# R7FA6E10F register map
Vendor: Renesas Electronics Corporation; Series: RA6; File version: 1.20.00
CPU: CM33 r0p4, little endian, MPU, FPU, VTOR, 4 interrupt priority bits, 96 interrupts
Registers are 8-bit, read-write, reset 0x0 unless marked. A register's access mark holds for its fields unless they carry their own. Offsets are from the block's base; [hi:lo] are bit positions; {n}, {i} and the like mark numbered series.

## SDHI0 — SD Host Interface 0
Base 0x40092000
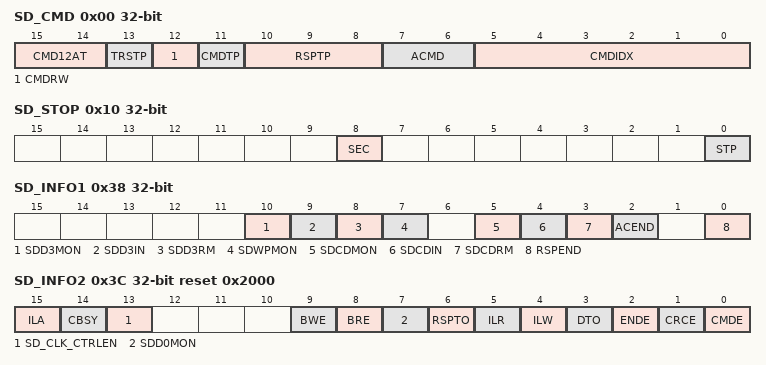
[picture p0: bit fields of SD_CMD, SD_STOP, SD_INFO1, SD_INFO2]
0x00 SD_CMD 32-bit — Command Type Register
  [15:14] CMD12AT — CMD12 Automatic Issue Select
    0=Automatically issue CMD12 during multiblock transfer; 1=Do not automatically issue CMD12 during multiblock transfer; other=Others (Setting prohibited)
  [13] TRSTP — Block Transfer Select
    0=Single block transfer; 1=Multiple blocks transfer
  [12] CMDRW — Data Transfer Direction Select
    0=Write (SD/MMC Host Interface → SD card/MMC); 1=Read (SD/MMC Host Interface ← SD card/MMC)
  [11] CMDTP — Data Transfer Select
    0=Do not include data transfer (bc, bcr, or ac) in command; 1=Include data transfer (adtc) in command
  [10:8] RSPTP — Response Type Select
    0=Normal mode Depending on the command, the response type and transfer method are selected in the ACMD[1:0] and CMDIDX[5:0] bits. At this time, the values for bits 15 to 11 in this register are invalid.; 3=Extended mode and no response; 4=Extended mode and R1, R5, R6, or R7 response; 5=Extended mode and R1b response; 6=Extended mode and R2 response; 7=Extended mode and R3 or R4 response; other=Others (Setting prohibited)
  [7:6] ACMD — Command Type Select
    0=CMD; 1=ACMD; other=Others (Setting prohibited)
  [5:0] CMDIDX — Command Index Field Value Select
    6=CMD6; 18=CMD18; 77=ACMD13
0x08 SD_ARG 32-bit — SD Command Argument Register
0x0C SD_ARG1 32-bit — SD Command Argument Register 1
0x10 SD_STOP 32-bit — Data Stop Register
  [8] SEC — Block Count Register Value Select
    0=Disable SD_SECCNT register value; 1=Enable SD_SECCNT register value
  [0] STP — Transfer Stop
0x14 SD_SECCNT 32-bit — Block Count Register
0x18 SD_RSP10 32-bit — SD Card Response Register 10
0x1C SD_RSP1 32-bit ro — SD Card Response Register 1
0x20 SD_RSP32 32-bit — SD Card Response Register 32
0x24 SD_RSP3 32-bit ro — SD Card Response Register 3
0x28 SD_RSP54 32-bit — SD Card Response Register 54
0x2C SD_RSP5 32-bit ro — SD Card Response Register 5
0x30 SD_RSP76 32-bit ro — SD Card Response Register 76
  [23:0] SD_RSP76 — These bits store the response from the SD card/MMC.
0x34 SD_RSP7 32-bit ro — SD Card Response Register 7
  [7:0] SD_RSP7 — These bits store the response from the SD card/MMC.
0x38 SD_INFO1 32-bit (reset mask 0xFFFFFB5F) — SD Card Interrupt Flag Register 1
  [10] SDD3MON ro — SDnDAT3 Pin Monitor Flag
    0=SDnDAT3 pin level is low; 1=SDnDAT3 pin level is high
  [9] SDD3IN — SDnDAT3 Insertion Flag
    0=SD card/MMC insertion not detected by the SDnDAT3 pin; 1=SD card/MMC insertion detected by the SDnDAT3 pin
  [8] SDD3RM — SDnDAT3 Removal Flag
    0=SD card/MMC removal not detected by the SDnDAT3 pin; 1=SD card/MMC removal detected by the SDnDAT3 pin
  [7] SDWPMON ro — SDnWP Pin Monitor Flag
    0=SDnWP pin level is high; 1=SDnWP pin level is low
  [5] SDCDMON ro — SDnCD Pin Monitor Flag
    0=SDnCD pin level is high; 1=SDnCD pin level is low
  [4] SDCDIN — SDnCD Insertion Flag
    0=SD card/MMC insertion not detected by the SDnCD pin; 1=SD card/MMC insertion detected by the SDnCD pin
  [3] SDCDRM — SDnCD Removal Flag
    0=SD card/MMC removal not detected by the SDnCD pin; 1=SD card/MMC removal detected by the SDnCD pin
  [2] ACEND — Access End Detection Flag
    0=Access end not detected; 1=Access end detected
  [0] RSPEND — Response End Detection Flag
    0=Response end not detected; 1=Response end detected
0x3C SD_INFO2 32-bit reset 0x2000 (reset mask 0xFFFFF77F) — SD Card Interrupt Flag Register 2
  [15] ILA — Illegal Access Error Detection Flag
    0=Illegal access error not detected; 1=Illegal access error detected
  [14] CBSY ro — Command Sequence Status Flag
    0=Command sequence complete; 1=Command sequence in progress (busy)
  [13] SD_CLK_CTRLEN ro — SD_CLK_CTRL Write Enable Flag
    0=SD/MMC bus (CMD and DAT lines) is busy, so write access to the SD_CLK_CTRL.CLKEN and CLKSEL[7:0] bits is disabled; 1=SD/MMC bus (CMD and DAT lines) is not busy, so write access to the SD_CLK_CTRL.CLKEN and CLKSEL[7:0] bits is enabled
  [9] BWE — SD_BUF0 Write Enable Flag
    0=Disable write access to the SD_BUF0 register; 1=Enable write access to the SD_BUF0 register
  [8] BRE — SD_BUF0 Read Enable Flag
    0=Disable read access to the SD_BUF0 register; 1=Enable read access to the SD_BUF0 register
  [7] SDD0MON ro — SDnDAT0 Pin Status Flag
    0=SDnDAT0 pin is low; 1=SDnDAT0 pin is high
  [6] RSPTO — Response Timeout Detection Flag
    0=Response timeout not detected; 1=Response timeout detected
  [5] ILR — SD_BUF0 Illegal Read Access Detection Flag
    0=Illegal read access to the SD_BUF0 register not detected; 1=Illegal read access to the SD_BUF0 register detected
  [4] ILW — SD_BUF0 Illegal Write Access Detection Flag
    0=Illegal write access to the SD_BUF0 register not detected; 1=Illegal write access to the SD_BUF0 register detected
  [3] DTO — Data Timeout Detection Flag
    0=Data timeout not detected; 1=Data timeout detected
  [2] ENDE — End Bit Error Detection Flag
    0=End bit error not detected; 1=End bit error detected
  [1] CRCE — CRC Error Detection Flag
    0=CRC error not detected; 1=CRC error detected
  [0] CMDE — Command Error Detection Flag
    0=Command error not detected; 1=Command error detected
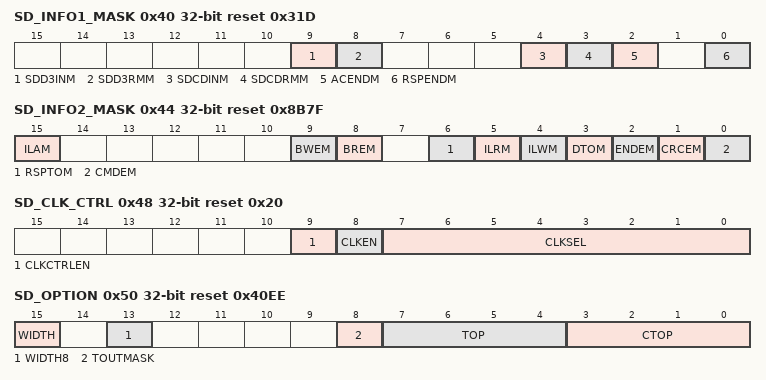
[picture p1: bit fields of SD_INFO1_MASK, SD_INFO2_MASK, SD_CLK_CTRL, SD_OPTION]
0x40 SD_INFO1_MASK 32-bit reset 0x31D — SD INFO1 Interrupt Mask Register
  [9] SDD3INM — SDnDAT3 Insertion Interrupt Request Mask
    0=Do not mask SD card/MMC insertion interrupt request by the SDnDAT3 pin; 1=Mask SD card/MMC insertion interrupt request by the SDnDAT3 pin
  [8] SDD3RMM — SDnDAT3 Removal Interrupt Request Mask
    0=Do not mask SD card/MMC removal interrupt request by the SDnDAT3 pin; 1=Mask SD card/MMC removal interrupt request by the SDnDAT3 pin
  [4] SDCDINM — SDnCD Insertion Interrupt Request Mask
    0=Do not mask SD card/MMC insertion interrupt request by the SDnCD pin; 1=Mask SD card/MMC insertion interrupt request by the SDnCD pin
  [3] SDCDRMM — SDnCD Removal Interrupt Request Mask
    0=Do not mask SD card/MMC removal interrupt request by the SDnCD pin; 1=Mask SD card/MMC removal interrupt request by the SDnCD pin
  [2] ACENDM — Access End Interrupt Request Mask
    0=Do not mask access end interrupt request; 1=Mask access end interrupt request
  [0] RSPENDM — Response End Interrupt Request Mask
    0=Do not mask response end interrupt request; 1=Mask response end interrupt request
0x44 SD_INFO2_MASK 32-bit reset 0x8B7F — SD INFO2 Interrupt Mask Register
  [15] ILAM — Illegal Access Error Interrupt Request Mask
    0=Do not mask illegal access error interrupt request; 1=Mask illegal access error interrupt request
  [9] BWEM — BWE Interrupt Request Mask
    0=Do not mask write enable interrupt request for the SD_BUF0 register; 1=Mask write enable interrupt request for the SD_BUF0 register
  [8] BREM — BRE Interrupt Request Mask
    0=Do not mask read enable interrupt request for the SD buffer; 1=Mask read enable interrupt request for the SD buffer
  [6] RSPTOM — Response Timeout Interrupt Request Mask
    0=Do not mask response timeout interrupt request; 1=Mask response timeout interrupt request
  [5] ILRM — SD_BUF0 Register Illegal Read Interrupt Request Mask
    0=Do not mask illegal read detection interrupt request for the SD_BUF0 register; 1=Mask illegal read detection interrupt request for the SD_BUF0 register
  [4] ILWM — SD_BUF0 Register Illegal Write Interrupt Request Mask
    0=Do not mask illegal write detection interrupt request for the SD_BUF0 register; 1=Mask illegal write detection interrupt request for the SD_BUF0 register
  [3] DTOM — Data Timeout Interrupt Request Mask
    0=Do not mask data timeout interrupt request; 1=Mask data timeout interrupt request
  [2] ENDEM — End Bit Error Interrupt Request Mask
    0=Do not mask end bit detection error interrupt request; 1=Mask end bit detection error interrupt request
  [1] CRCEM — CRC Error Interrupt Request Mask
    0=Do not mask CRC error interrupt request; 1=Mask CRC error interrupt request
  [0] CMDEM — Command Error Interrupt Request Mask
    0=Do not mask command error interrupt request; 1=Mask command error interrupt request
0x48 SD_CLK_CTRL 32-bit reset 0x20 — SD Clock Control Register
  [9] CLKCTRLEN — SD/MMC Clock Output Automatic Control Select
    0=Disable automatic control of SD/MMC clock output; 1=Enable automatic control of SD/MMC clock output
  [8] CLKEN — SD/MMC Clock Output Control
    0=Disable SD/MMC clock output (fix SDnCLK signal low); 1=Enable SD/MMC clock output
  [7:0] CLKSEL — SDHI Clock Frequency Select
    255=PCLKB; 0=PCLKB/2; 1=PCLKB/4; 2=PCLKB/8; 4=PCLKB/16; 8=PCLKB/32; 16=PCLKB/64; 32=PCLKB/128; 64=PCLKB/256; 128=PCLKB/512; other=Others (Setting prohibited)
0x4C SD_SIZE 32-bit reset 0x200 — Transfer Data Length Register
  [9:0] LEN — Transfer Data Size Setting
0x50 SD_OPTION 32-bit reset 0x40EE — SD Card Access Control Option Register
  [15] WIDTH — Bus Width
  [13] WIDTH8 — Bus Width
  [8] TOUTMASK — Timeout Mask
    0=Activate timeout; 1=Inactivate timeout (do not set RSPTO and DTO bits of SD_INFO2 or CRCBSYTO, CRCTO, RDTO, BSYTO1, BSYTO0, RSPTO1 and RSPTO0 bits of SD_ERR_STS2) When timeout occurs because of an inactivated timeout, execute a software reset to terminate the command sequence
  [7:4] TOP — Timeout Counter
    {v}=SD/MMC clock × {v+213} (v=0..14); 15=Setting prohibited
  [3:0] CTOP — Card Detection Time Counter
    {v}=PCLKB × {v+210} (v=0..14); 15=Setting prohibited
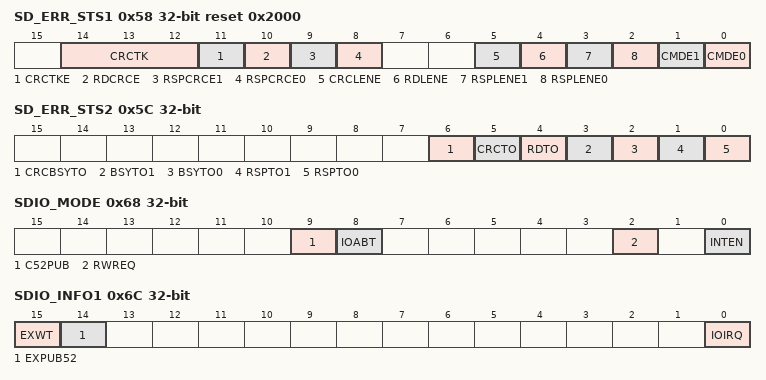
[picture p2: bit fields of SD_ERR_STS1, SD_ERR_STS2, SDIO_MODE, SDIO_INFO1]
0x58 SD_ERR_STS1 32-bit ro reset 0x2000 — SD Error Status Register 1
  [14:12] CRCTK — CRC Status Token
  [11] CRCTKE — CRC Status Token Error Flag
    0=No error detected in CRC status token; 1=Error detected in CRC status token
  [10] RDCRCE — Read Data CRC Error Flag
    0=No CRC error detected in read data; 1=CRC error detected in read data
  [9] RSPCRCE1 — Response CRC Error Flag 1
    0=No CRC error detected in command response (with SD_CMD.CMDIDX[5:0] setting, an error that occurs with CMD12 issue is indicated in the RSPCRCE0 flag); 1=CRC error detected in command response
  [8] RSPCRCE0 — Response CRC Error Flag 0
    0=No CRC error detected in command response; 1=CRC error detected in command response
  [5] CRCLENE — CRC Status Token Length Error Flag
    0=No CRC status token length error occurred; 1=CRC status token length error occurred
  [4] RDLENE — Read Data Length Error Flag
    0=No read data length error occurred; 1=Read data length error occurred
  [3] RSPLENE1 — Response Length Error Flag 1
    0=No error exists in command response length; 1=Error exists in command response length (with SD_CMD.CMDIDX[5:0] setting, an error that occurs with CMD12 issue is indicated in the RSPLENE0 flag)
  [2] RSPLENE0 — Response Length Error Flag 0
    0=No error exists in command response length; 1=Error exists in command response length
  [1] CMDE1 — Command Error Flag 1
    0=No error exists in command index field value of a command response; 1=Error exists in command index field value of a command response (with SD_CMD.CMDIDX[5:0] setting, an error that occurs with CMD12 issue is indicated in the CMDE0 flag)
  [0] CMDE0 — Command Error Flag 0
    0=No error exists in command index field value of a command response; 1=Error exists in command index field value of a command response
0x5C SD_ERR_STS2 32-bit ro — SD Error Status Register 2
  [6] CRCBSYTO — CRC Status Token Busy Timeout Flag
    0=After a CRC status token was received, the SD/MMC was released from the busy state during the specified period; 1=After a CRC status token was received, the SD/MMC was in the busy state after the specified period elapsed
  [5] CRCTO — CRC Status Token Timeout Flag
    0=After CRC data was written to the SD card/MMC, a CRC status token was received during the specified period; 1=After CRC data was written to the SD card/MMC, a CRC status token was not received after the specified period elapsed
  [4] RDTO — Read Data Timeout Flag
  [3] BSYTO1 — Busy Timeout Flag 1
    0=After CMD12 was automatically issued, SD/MMC was released from the busy state during the specified period; 1=After CMD12 was automatically issued, SD/MMC was in the busy state after the specified period elapsed (with SD_CMD.CMDIDX[5:0] setting, an error that occurs with CMD12 issue is indicated in the BSYTO0 flag)
  [2] BSYTO0 — Busy Timeout Flag 0
    0=After R1b response was received, SD/MMC was released from the busy state during the specified period; 1=After R1b response was received, SD/MMC was in the busy state after the specified period elapsed
  [1] RSPTO1 — Response Timeout Flag 1
    0=After command was issued, response was received in less than 640 cycles of the SD/MMC clock; 1=After command was issued, response was not received after 640 or more cycles of the SD/MMC clock (with SD_CMD.CMDIDX[5:0] setting, an error that occurs with CMD12 issue is indicated in the RSPTO0 flag)
  [0] RSPTO0 — Response Timeout Flag 0
    0=After command was issued, response was received in less than 640 cycles of the SD/MMC clock; 1=After command was issued, response was not received in 640 or more cycles of the SD/MMC clock
0x60 SD_BUF0 32-bit reset not defined — SD Buffer Register
0x68 SDIO_MODE 32-bit — SDIO Mode Control Register
  [9] C52PUB — SDIO None Abort
  [8] IOABT — SDIO Abort
  [2] RWREQ — Read Wait Request
    0=Allow SD/MMC to exit read wait state; 1=Request for SD/MMC to enter read wait state
  [0] INTEN — SDIO Interrupt Acceptance Enable
    0=Disable SDIO interrupt acceptance; 1=Enable SDIO interrupt acceptance
0x6C SDIO_INFO1 32-bit — SDIO Interrupt Flag Register
  [15] EXWT — EXWT Status Flag
  [14] EXPUB52 — EXPUB52 Status Flag
  [0] IOIRQ — SDIO Interrupt Status Flag
    0=No SDIO interrupt detected; 1=SDIO interrupt detected
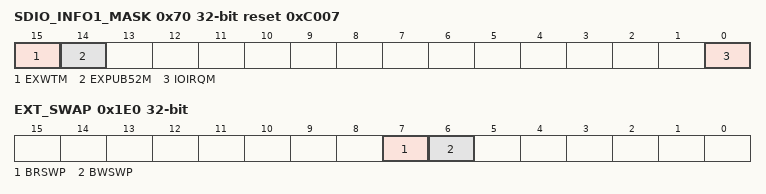
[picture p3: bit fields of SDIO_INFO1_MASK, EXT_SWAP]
0x70 SDIO_INFO1_MASK 32-bit reset 0xC007 — SDIO INFO1 Interrupt Mask Register
  [15] EXWTM — EXWT Interrupt Request Mask Control
    0=Do not mask EXWT interrupt requests; 1=Mask EXWT interrupt requests
  [14] EXPUB52M — EXPUB52 Interrupt Request Mask Control
    0=Do not mask EXPUB52 interrupt requests; 1=Mask EXPUB52 interrupt requests
  [0] IOIRQM — IOIRQ Interrupt Mask Control
    0=Do not mask IOIRQ interrupts; 1=Mask IOIRQ interrupts
0x1B0 SD_DMAEN 32-bit reset 0x1010 — DMA Mode Enable Register
  [1] DMAEN — DMA Transfer Enable
    0=Disable use of DMA transfer to access SD_BUF0 register; 1=Enable use of DMA transfer to access SD_BUF0 register
0x1C0 SOFT_RST 32-bit reset 0x7 — Software Reset Register
  [0] SDRST — Software Reset Control
    0=Reset SD/MMC Host Interface software; 1=Cancel reset of SD/MMC Host Interface software
0x1CC SDIF_MODE 32-bit — SD Interface Mode Setting Register
  [8] NOCHKCR — CRC Check Mask
    0=Enable CRC check; 1=Disable CRC Check (ignore CRC16 valued when reading and ignore CRC status value when writing)
0x1E0 EXT_SWAP 32-bit — Swap Control Register
  [7] BRSWP — SD_BUF0 Swap Read
    0=Normal read operation; 1=Swap the byte endian order before reading SD_BUF0 register
  [6] BWSWP — SD_BUF0 Swap Write
    0=Normal write operation; 1=Swap the byte endian order before writing to SD_BUF0 register
